AUTOSAR XML (schema 4-2-2)
package /ComponentTypes
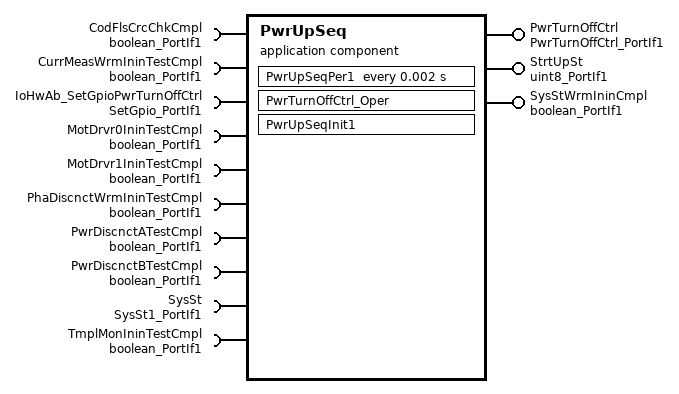
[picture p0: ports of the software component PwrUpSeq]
  application sw component type PwrUpSeq
    provide port PwrTurnOffCtrl: server-com-spec{operation=Oper, queue-length=1}, provided-interface=PwrTurnOffCtrl_PortIf1
    provide port StrtUpSt: nonqueued-sender-com-spec{data-element=Val, init-value=0}, provided-interface=uint8_PortIf1
    provide port SysStWrmIninCmpl: nonqueued-sender-com-spec{data-element=Logl, init-value=0}, provided-interface=boolean_PortIf1
    10 x require port:
      CodFlsCrcChkCmpl: nonqueued-receiver-com-spec{data-element=Logl, filter=data-filter-type=ALWAYS, init-value=0}, required-interface=boolean_PortIf1
      CurrMeasWrmIninTestCmpl: nonqueued-receiver-com-spec{data-element=Logl, filter=data-filter-type=ALWAYS, init-value=0}, required-interface=boolean_PortIf1
      IoHwAb_SetGpioPwrTurnOffCtrl: client-com-spec=Oper, required-interface=SetGpio_PortIf1
      MotDrvr0IninTestCmpl: nonqueued-receiver-com-spec{data-element=Logl, filter=data-filter-type=ALWAYS, init-value=0}, required-interface=boolean_PortIf1
      MotDrvr1IninTestCmpl: nonqueued-receiver-com-spec{data-element=Logl, filter=data-filter-type=ALWAYS, init-value=0}, required-interface=boolean_PortIf1
      PhaDiscnctWrmIninTestCmpl: nonqueued-receiver-com-spec{data-element=Logl, filter=data-filter-type=ALWAYS, init-value=0}, required-interface=boolean_PortIf1
      PwrDiscnctATestCmpl: nonqueued-receiver-com-spec{data-element=Logl, filter=data-filter-type=ALWAYS, init-value=0}, required-interface=boolean_PortIf1
      PwrDiscnctBTestCmpl: nonqueued-receiver-com-spec{data-element=Logl, filter=data-filter-type=ALWAYS, init-value=0}, required-interface=boolean_PortIf1
      SysSt: nonqueued-receiver-com-spec{data-element=Val, filter=data-filter-type=ALWAYS, init-value=3}, required-interface=SysSt1_PortIf1
      TmplMonIninTestCmpl: nonqueued-receiver-com-spec{data-element=Logl, filter=data-filter-type=ALWAYS, init-value=0}, required-interface=boolean_PortIf1
    behavior PwrUpSeq_InternalBehavior
      ar-typed-per-instance-memorys:
        data PwrTurnOffCtrlPrev: sw-calibration-access=READ-ONLY, type=uint8
      operation invoked event OIT_PwrTurnOffCtrl_Oper_PwrTurnOffCtrl_Oper: start-on-event=PwrTurnOffCtrl_Oper, operation=PwrTurnOffCtrl.Oper
      init event PwrUpSeqInit1_InitEvent: start-on-event=PwrUpSeqInit1
      timing event TMT_PwrUpSeqPer1: start-on-event=PwrUpSeqPer1, period=0.002
      port-api-options:
        enable-take-address=false, error-handling=NO-TRANSFORMER-ERROR-HANDLING, indirect-api=false, port=CodFlsCrcChkCmpl
        enable-take-address=false, error-handling=NO-TRANSFORMER-ERROR-HANDLING, indirect-api=false, port=CurrMeasWrmIninTestCmpl
        enable-take-address=false, error-handling=NO-TRANSFORMER-ERROR-HANDLING, indirect-api=false, port=IoHwAb_SetGpioPwrTurnOffCtrl
        enable-take-address=false, error-handling=NO-TRANSFORMER-ERROR-HANDLING, indirect-api=false, port=MotDrvr0IninTestCmpl
        enable-take-address=false, error-handling=NO-TRANSFORMER-ERROR-HANDLING, indirect-api=false, port=MotDrvr1IninTestCmpl
        enable-take-address=false, error-handling=NO-TRANSFORMER-ERROR-HANDLING, indirect-api=false, port=PwrDiscnctATestCmpl
        enable-take-address=false, error-handling=NO-TRANSFORMER-ERROR-HANDLING, indirect-api=false, port=PwrDiscnctBTestCmpl
        enable-take-address=false, error-handling=NO-TRANSFORMER-ERROR-HANDLING, indirect-api=false, port=PwrTurnOffCtrl
        enable-take-address=false, error-handling=NO-TRANSFORMER-ERROR-HANDLING, indirect-api=false, port=StrtUpSt
        enable-take-address=false, error-handling=NO-TRANSFORMER-ERROR-HANDLING, indirect-api=false, port=SysSt
        enable-take-address=false, error-handling=NO-TRANSFORMER-ERROR-HANDLING, indirect-api=false, port=SysStWrmIninCmpl
        enable-take-address=false, error-handling=NO-TRANSFORMER-ERROR-HANDLING, indirect-api=false, port=TmplMonIninTestCmpl
      runnable PwrTurnOffCtrl_Oper
        sync call SC_IoHwAb_SetGpioPwrTurnOffCtrl_Oper: operation=IoHwAb_SetGpioPwrTurnOffCtrl.Oper, timeout=0
      runnable PwrUpSeqInit1
      runnable PwrUpSeqPer1
        data-receive-point-by-arguments:
          9 x access:
            REC_CodFlsCrcChkCmpl_Logl: accessed-variable=CodFlsCrcChkCmpl.Logl
            REC_CurrMeasWrmIninTestCmpl_Logl: accessed-variable=CurrMeasWrmIninTestCmpl.Logl
            REC_MotDrvr0IninTestCmpl_Logl: accessed-variable=MotDrvr0IninTestCmpl.Logl
            REC_MotDrvr1IninTestCmpl_Logl: accessed-variable=MotDrvr1IninTestCmpl.Logl
            REC_PhaDiscnctWrmIninTestCmpl_Logl: accessed-variable=PhaDiscnctWrmIninTestCmpl.Logl
            REC_PwrDiscnctATestCmpl_Logl: accessed-variable=PwrDiscnctATestCmpl.Logl
            REC_PwrDiscnctBTestCmpl_Logl: accessed-variable=PwrDiscnctBTestCmpl.Logl
            REC_SysSt_Val: accessed-variable=SysSt.Val
            REC_TmplMonIninTestCmpl_Logl: accessed-variable=TmplMonIninTestCmpl.Logl
        data-send-points:
          access SEND_StrtUpSt_Val: accessed-variable=StrtUpSt.Val
          access SEND_SysStWrmIninCmpl_Logl: accessed-variable=SysStWrmIninCmpl.Logl
  swc implementation PwrUpSeq_Implementation: behavior=PwrUpSeq_InternalBehavior
    code-descriptors:
      code Default: artifact-descriptors=autosar-engineering-object={short-label=Default, category=SWSRC}
